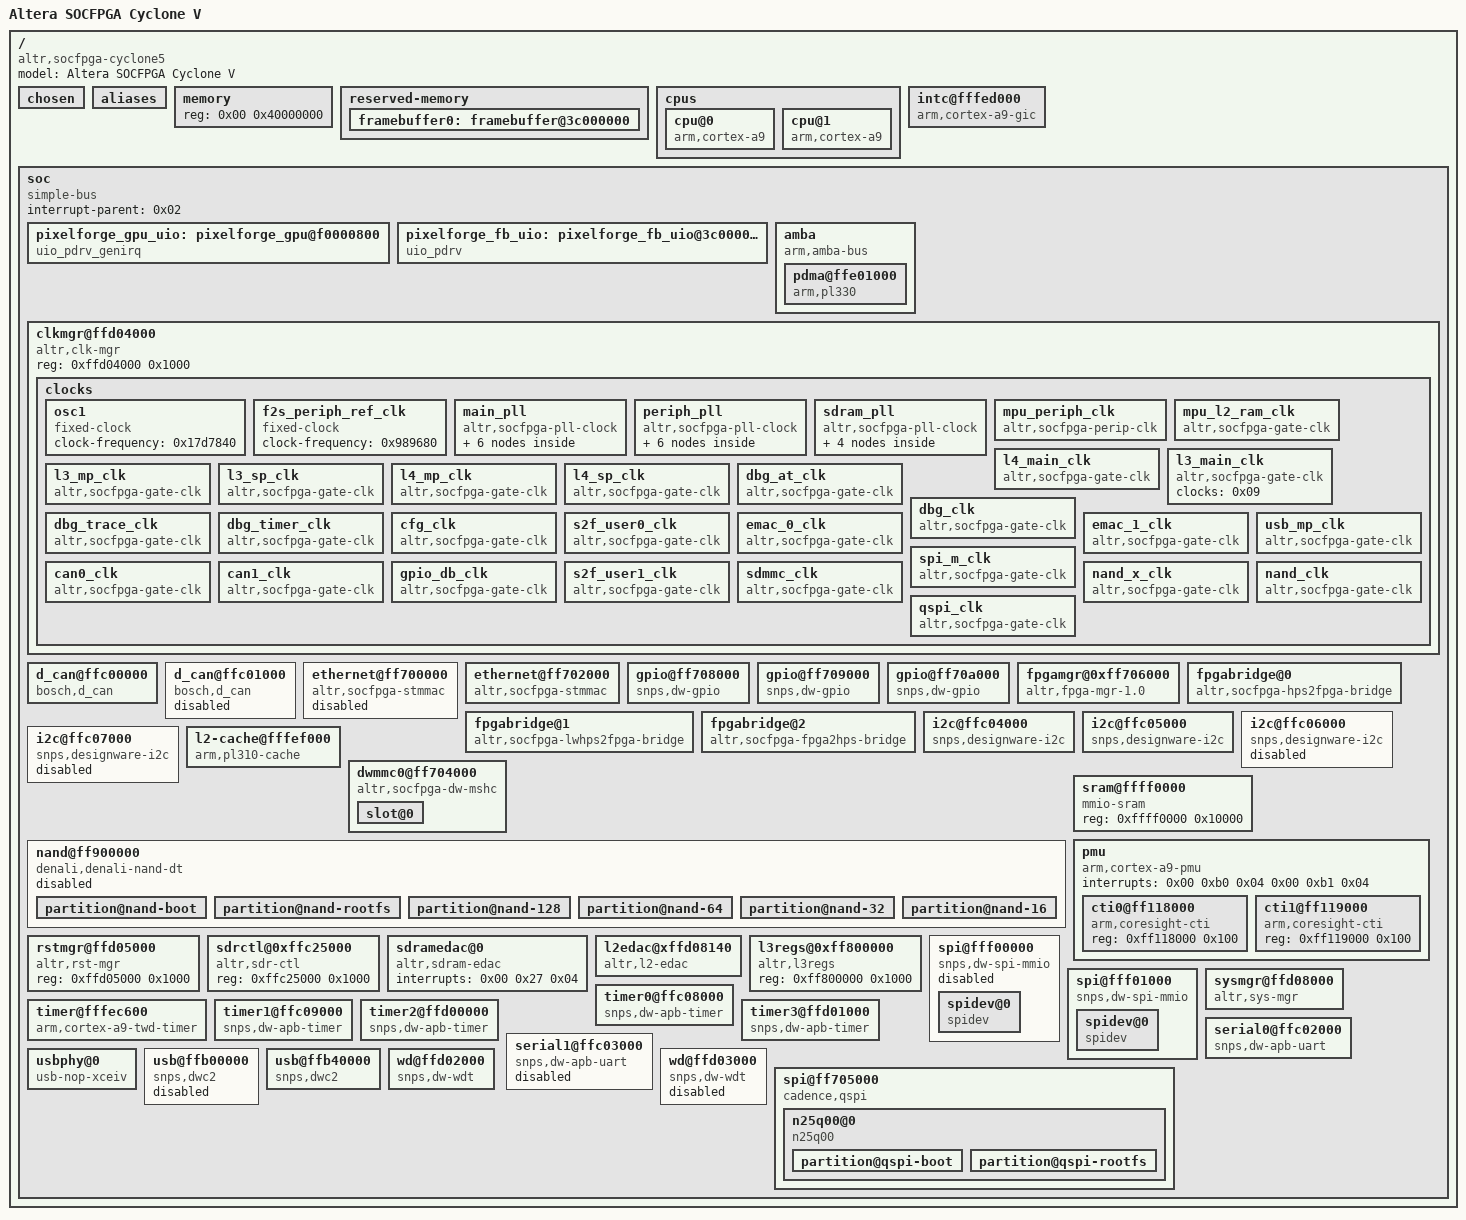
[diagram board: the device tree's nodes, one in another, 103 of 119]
/dts-v1/;

/ {
	#address-cells = <0x01>;
	#size-cells = <0x01>;
	model = "Altera SOCFPGA Cyclone V";
	compatible = "altr,socfpga-cyclone5", "altr,socfpga";

	chosen {
		bootargs = "console=ttyS0,115200 root=/dev/mmcblk0p2 rw rootwait";
	};

	aliases {
		serial0 = "/soc/serial0@ffc02000";
		serial1 = "/soc/serial1@ffc03000";
		timer0 = "/soc/timer0@ffc08000";
		timer1 = "/soc/timer1@ffc09000";
		timer2 = "/soc/timer2@ffd00000";
		timer3 = "/soc/timer3@ffd01000";
		ethernet0 = "/soc/ethernet@ff702000";
	};

	memory {
		device_type = "memory";
		reg = <0x00 0x40000000>;
	};

	/* Reserved contiguous VRAM carveout (64MB at top of 1GB SDRAM) */
	reserved-memory {
		#address-cells = <1>;
		#size-cells = <1>;
		ranges;

		/* 0x3c000000 - 0x3fffffff reserved for VRAM (color/depth/stencil/other GPU buffers) */
		framebuffer0: framebuffer@3c000000 {
			reg = <0x3c000000 0x04000000>; /* 64MB */
			no-map; /* prevent kernel usage/mapping */
		};
	};

	cpus {
		#address-cells = <0x01>;
		#size-cells = <0x00>;

		cpu@0 {
			compatible = "arm,cortex-a9";
			device_type = "cpu";
			reg = <0x00>;
			next-level-cache = <0x01>;
		};

		cpu@1 {
			compatible = "arm,cortex-a9";
			device_type = "cpu";
			reg = <0x01>;
			next-level-cache = <0x01>;
		};
	};

	intc@fffed000 {
		compatible = "arm,cortex-a9-gic";
		#interrupt-cells = <0x03>;
		interrupt-controller;
		reg = <0xfffed000 0x1000 0xfffec100 0x100>;
		linux,phandle = <0x02>;
		phandle = <0x02>;
	};

	soc {
		#address-cells = <0x01>;
		#size-cells = <0x01>;
		compatible = "simple-bus";
		device_type = "soc";
		interrupt-parent = <0x02>;
		ranges;

		/* UIO device for PixelForge GPU CSR window with IRQ3 (ready) */
		pixelforge_gpu_uio: pixelforge_gpu@f0000800 {
			compatible = "uio_pdrv_genirq";
			reg = <0xF0000800 0x00001000>;
			interrupt-parent = <0x02>;
			interrupts = <0 75 4>; /* GIC SPI 75, level-high: adjust if needed */
			uio-name = "pixelforge_gpu";
		};

		/* UIO mapping for reserved VRAM region (no IRQ) */
		pixelforge_fb_uio: pixelforge_fb_uio@3c000000 {
			compatible = "uio_pdrv";
			reg = <0x3c000000 0x04000000>;
			uio-name = "pixelforge_fb";
		};

		amba {
			compatible = "arm,amba-bus";
			#address-cells = <0x01>;
			#size-cells = <0x01>;
			ranges;

			pdma@ffe01000 {
				compatible = "arm,pl330", "arm,primecell";
				reg = <0xffe01000 0x1000>;
				#dma-cells = <0x01>;
				#dma-channels = <0x08>;
				#dma-requests = <0x20>;
				interrupts = <0x00 0x68 0x04>;
				nr-irqs = <0x09>;
				nr-valid-peri = <0x20>;
				clocks = <0x03>;
				clock-names = "apb_pclk";
				copy-align = <0x03>;
				linux,phandle = <0x1c>;
				phandle = <0x1c>;
			};
		};

		clkmgr@ffd04000 {
			compatible = "altr,clk-mgr";
			reg = <0xffd04000 0x1000>;

			clocks {
				#address-cells = <0x01>;
				#size-cells = <0x00>;

				osc1 {
					#clock-cells = <0x00>;
					compatible = "fixed-clock";
					clock-frequency = <0x17d7840>;
					linux,phandle = <0x04>;
					phandle = <0x04>;
				};

				f2s_periph_ref_clk {
					#clock-cells = <0x00>;
					compatible = "fixed-clock";
					clock-frequency = <0x989680>;
					linux,phandle = <0x12>;
					phandle = <0x12>;
				};

				main_pll {
					#address-cells = <0x01>;
					#size-cells = <0x00>;
					#clock-cells = <0x00>;
					compatible = "altr,socfpga-pll-clock";
					clocks = <0x04>;
					reg = <0x40>;
					linux,phandle = <0x05>;
					phandle = <0x05>;

					mpuclk {
						#clock-cells = <0x00>;
						compatible = "altr,socfpga-perip-clk";
						clocks = <0x05>;
						fixed-divider = <0x02>;
						reg = <0x48>;
						linux,phandle = <0x08>;
						phandle = <0x08>;
					};

					mainclk {
						#clock-cells = <0x00>;
						compatible = "altr,socfpga-perip-clk";
						clocks = <0x05>;
						fixed-divider = <0x04>;
						reg = <0x4c>;
						linux,phandle = <0x09>;
						phandle = <0x09>;
					};

					dbg_base_clk {
						#clock-cells = <0x00>;
						compatible = "altr,socfpga-perip-clk";
						clocks = <0x05>;
						fixed-divider = <0x04>;
						reg = <0x50>;
						linux,phandle = <0x0c>;
						phandle = <0x0c>;
					};

					main_qspi_clk {
						#clock-cells = <0x00>;
						compatible = "altr,socfpga-perip-clk";
						clocks = <0x05>;
						reg = <0x54>;
						linux,phandle = <0x15>;
						phandle = <0x15>;
					};

					main_nand_sdmmc_clk {
						#clock-cells = <0x00>;
						compatible = "altr,socfpga-perip-clk";
						clocks = <0x05>;
						reg = <0x58>;
						linux,phandle = <0x13>;
						phandle = <0x13>;
					};

					cfg_s2f_usr0_clk {
						#clock-cells = <0x00>;
						compatible = "altr,socfpga-perip-clk";
						clocks = <0x05>;
						reg = <0x5c>;
						linux,phandle = <0x0e>;
						phandle = <0x0e>;
					};
				};

				periph_pll {
					#address-cells = <0x01>;
					#size-cells = <0x00>;
					#clock-cells = <0x00>;
					compatible = "altr,socfpga-pll-clock";
					clocks = <0x04>;
					reg = <0x80>;
					linux,phandle = <0x06>;
					phandle = <0x06>;

					emac0_clk {
						#clock-cells = <0x00>;
						compatible = "altr,socfpga-perip-clk";
						clocks = <0x06>;
						reg = <0x88>;
						linux,phandle = <0x0f>;
						phandle = <0x0f>;
					};

					emac1_clk {
						#clock-cells = <0x00>;
						compatible = "altr,socfpga-perip-clk";
						clocks = <0x06>;
						reg = <0x8c>;
						linux,phandle = <0x10>;
						phandle = <0x10>;
					};

					per_qsi_clk {
						#clock-cells = <0x00>;
						compatible = "altr,socfpga-perip-clk";
						clocks = <0x06>;
						reg = <0x90>;
						linux,phandle = <0x16>;
						phandle = <0x16>;
					};

					per_nand_mmc_clk {
						#clock-cells = <0x00>;
						compatible = "altr,socfpga-perip-clk";
						clocks = <0x06>;
						reg = <0x94>;
						linux,phandle = <0x14>;
						phandle = <0x14>;
					};

					per_base_clk {
						#clock-cells = <0x00>;
						compatible = "altr,socfpga-perip-clk";
						clocks = <0x06>;
						reg = <0x98>;
						linux,phandle = <0x0b>;
						phandle = <0x0b>;
					};

					s2f_usr1_clk {
						#clock-cells = <0x00>;
						compatible = "altr,socfpga-perip-clk";
						clocks = <0x06>;
						reg = <0x9c>;
						linux,phandle = <0x11>;
						phandle = <0x11>;
					};
				};

				sdram_pll {
					#address-cells = <0x01>;
					#size-cells = <0x00>;
					#clock-cells = <0x00>;
					compatible = "altr,socfpga-pll-clock";
					clocks = <0x04>;
					reg = <0xc0>;
					linux,phandle = <0x07>;
					phandle = <0x07>;

					ddr_dqs_clk {
						#clock-cells = <0x00>;
						compatible = "altr,socfpga-perip-clk";
						clocks = <0x07>;
						reg = <0xc8>;
					};

					ddr_2x_dqs_clk {
						#clock-cells = <0x00>;
						compatible = "altr,socfpga-perip-clk";
						clocks = <0x07>;
						reg = <0xcc>;
					};

					ddr_dq_clk {
						#clock-cells = <0x00>;
						compatible = "altr,socfpga-perip-clk";
						clocks = <0x07>;
						reg = <0xd0>;
					};

					s2f_usr2_clk {
						#clock-cells = <0x00>;
						compatible = "altr,socfpga-perip-clk";
						clocks = <0x07>;
						reg = <0xd4>;
					};
				};

				mpu_periph_clk {
					#clock-cells = <0x00>;
					compatible = "altr,socfpga-perip-clk";
					clocks = <0x08>;
					fixed-divider = <0x04>;
					linux,phandle = <0x1d>;
					phandle = <0x1d>;
				};

				mpu_l2_ram_clk {
					#clock-cells = <0x00>;
					compatible = "altr,socfpga-gate-clk";
					clocks = <0x08>;
					fixed-divider = <0x02>;
				};

				l4_main_clk {
					#clock-cells = <0x00>;
					compatible = "altr,socfpga-gate-clk";
					clocks = <0x09>;
					clk-gate = <0x60 0x00>;
					linux,phandle = <0x03>;
					phandle = <0x03>;
				};

				l3_main_clk {
					#clock-cells = <0x00>;
					compatible = "altr,socfpga-gate-clk";
					clocks = <0x09>;
				};

				l3_mp_clk {
					#clock-cells = <0x00>;
					compatible = "altr,socfpga-gate-clk";
					clocks = <0x09>;
					div-reg = <0x64 0x00 0x02>;
					clk-gate = <0x60 0x01>;
					linux,phandle = <0x0a>;
					phandle = <0x0a>;
				};

				l3_sp_clk {
					#clock-cells = <0x00>;
					compatible = "altr,socfpga-gate-clk";
					clocks = <0x0a>;
					div-reg = <0x64 0x02 0x02>;
				};

				l4_mp_clk {
					#clock-cells = <0x00>;
					compatible = "altr,socfpga-gate-clk";
					clocks = <0x09 0x0b>;
					div-reg = <0x64 0x04 0x03>;
					clk-gate = <0x60 0x02>;
					linux,phandle = <0x19>;
					phandle = <0x19>;
				};

				l4_sp_clk {
					#clock-cells = <0x00>;
					compatible = "altr,socfpga-gate-clk";
					clocks = <0x09 0x0b>;
					div-reg = <0x64 0x07 0x03>;
					clk-gate = <0x60 0x03>;
					linux,phandle = <0x1e>;
					phandle = <0x1e>;
				};

				dbg_at_clk {
					#clock-cells = <0x00>;
					compatible = "altr,socfpga-gate-clk";
					clocks = <0x0c>;
					div-reg = <0x68 0x00 0x02>;
					clk-gate = <0x60 0x04>;
					linux,phandle = <0x0d>;
					phandle = <0x0d>;
				};

				dbg_clk {
					#clock-cells = <0x00>;
					compatible = "altr,socfpga-gate-clk";
					clocks = <0x0d>;
					div-reg = <0x68 0x02 0x02>;
					clk-gate = <0x60 0x05>;
				};

				dbg_trace_clk {
					#clock-cells = <0x00>;
					compatible = "altr,socfpga-gate-clk";
					clocks = <0x0c>;
					div-reg = <0x6c 0x00 0x03>;
					clk-gate = <0x60 0x06>;
				};

				dbg_timer_clk {
					#clock-cells = <0x00>;
					compatible = "altr,socfpga-gate-clk";
					clocks = <0x0c>;
					clk-gate = <0x60 0x07>;
				};

				cfg_clk {
					#clock-cells = <0x00>;
					compatible = "altr,socfpga-gate-clk";
					clocks = <0x0e>;
					clk-gate = <0x60 0x08>;
				};

				s2f_user0_clk {
					#clock-cells = <0x00>;
					compatible = "altr,socfpga-gate-clk";
					clocks = <0x0e>;
					clk-gate = <0x60 0x09>;
				};

				emac_0_clk {
					#clock-cells = <0x00>;
					compatible = "altr,socfpga-gate-clk";
					clocks = <0x0f>;
					clk-gate = <0xa0 0x00>;
				};

				emac_1_clk {
					#clock-cells = <0x00>;
					compatible = "altr,socfpga-gate-clk";
					clocks = <0x10>;
					clk-gate = <0xa0 0x01>;
				};

				usb_mp_clk {
					#clock-cells = <0x00>;
					compatible = "altr,socfpga-gate-clk";
					clocks = <0x0b>;
					clk-gate = <0xa0 0x02>;
					div-reg = <0xa4 0x00 0x03>;
					linux,phandle = <0x1f>;
					phandle = <0x1f>;
				};

				spi_m_clk {
					#clock-cells = <0x00>;
					compatible = "altr,socfpga-gate-clk";
					clocks = <0x0b>;
					clk-gate = <0xa0 0x03>;
					div-reg = <0xa4 0x03 0x03>;
				};

				can0_clk {
					#clock-cells = <0x00>;
					compatible = "altr,socfpga-gate-clk";
					clocks = <0x0b>;
					clk-gate = <0xa0 0x04>;
					div-reg = <0xa4 0x06 0x03>;
					linux,phandle = <0x17>;
					phandle = <0x17>;
				};

				can1_clk {
					#clock-cells = <0x00>;
					compatible = "altr,socfpga-gate-clk";
					clocks = <0x0b>;
					clk-gate = <0xa0 0x05>;
					div-reg = <0xa4 0x09 0x03>;
					linux,phandle = <0x18>;
					phandle = <0x18>;
				};

				gpio_db_clk {
					#clock-cells = <0x00>;
					compatible = "altr,socfpga-gate-clk";
					clocks = <0x0b>;
					clk-gate = <0xa0 0x06>;
					div-reg = <0xa8 0x00 0x18>;
				};

				s2f_user1_clk {
					#clock-cells = <0x00>;
					compatible = "altr,socfpga-gate-clk";
					clocks = <0x11>;
					clk-gate = <0xa0 0x07>;
				};

				sdmmc_clk {
					#clock-cells = <0x00>;
					compatible = "altr,socfpga-gate-clk";
					clocks = <0x12 0x13 0x14>;
					clk-gate = <0xa0 0x08>;
					linux,phandle = <0x1a>;
					phandle = <0x1a>;
				};

				nand_x_clk {
					#clock-cells = <0x00>;
					compatible = "altr,socfpga-gate-clk";
					clocks = <0x12 0x13 0x14>;
					clk-gate = <0xa0 0x09>;
				};

				nand_clk {
					#clock-cells = <0x00>;
					compatible = "altr,socfpga-gate-clk";
					clocks = <0x12 0x13 0x14>;
					clk-gate = <0xa0 0x0a>;
					fixed-divider = <0x04>;
					linux,phandle = <0x1b>;
					phandle = <0x1b>;
				};

				qspi_clk {
					#clock-cells = <0x00>;
					compatible = "altr,socfpga-gate-clk";
					clocks = <0x12 0x15 0x16>;
					clk-gate = <0xa0 0x0b>;
				};
			};
		};

		d_can@ffc00000 {
			compatible = "bosch,d_can";
			reg = <0xffc00000 0x1000>;
			interrupts = <0x00 0x83 0x04 0x00 0x84 0x04>;
			clocks = <0x17>;
			status = "okay";
		};

		d_can@ffc01000 {
			compatible = "bosch,d_can";
			reg = <0xffc01000 0x1000>;
			interrupts = <0x00 0x87 0x04 0x00 0x88 0x04>;
			clocks = <0x18>;
			status = "disabled";
		};

		ethernet@ff700000 {
			compatible = "altr,socfpga-stmmac", "snps,dwmac-3.70a", "snps,dwmac";
			reg = <0xff700000 0x2000>;
			interrupts = <0x00 0x73 0x04>;
			interrupt-names = "macirq";
			mac-address = [00 00 00 00 00 00];
			clocks = <0x0f>;
			clock-names = "stmmaceth";
			status = "disabled";
		};

		ethernet@ff702000 {
			compatible = "altr,socfpga-stmmac", "snps,dwmac-3.70a", "snps,dwmac";
			reg = <0xff702000 0x2000>;
			interrupts = <0x00 0x78 0x04>;
			interrupt-names = "macirq";
			mac-address = [00 00 00 00 00 00];
			clocks = <0x10>;
			clock-names = "stmmaceth";
			status = "okay";
			phy-mode = "rgmii";
			snps,phy-addr = <0xffffffff>;
			rxd0-skew-ps = <0x00>;
			rxd1-skew-ps = <0x00>;
			rxd2-skew-ps = <0x00>;
			rxd3-skew-ps = <0x00>;
			txen-skew-ps = <0x00>;
			txc-skew-ps = <0xa28>;
			rxdv-skew-ps = <0x00>;
			rxc-skew-ps = <0x7d0>;
			snps,max-mtu = <0xed8>;
		};

		gpio@ff708000 {
			compatible = "snps,dw-gpio";
			reg = <0xff708000 0x1000>;
			interrupts = <0x00 0xa4 0x04>;
			width = <0x1d>;
			virtual_irq_start = <0x101>;
			interrupt-controller;
			#interrupt-cells = <0x02>;
			gpio-controller;
			#gpio-cells = <0x02>;
			clocks = <0x0b>;
		};

		gpio@ff709000 {
			compatible = "snps,dw-gpio";
			reg = <0xff709000 0x1000>;
			interrupts = <0x00 0xa5 0x04>;
			width = <0x1d>;
			virtual_irq_start = <0x11e>;
			interrupt-controller;
			#interrupt-cells = <0x02>;
			gpio-controller;
			#gpio-cells = <0x02>;
			clocks = <0x0b>;
		};

		gpio@ff70a000 {
			compatible = "snps,dw-gpio";
			reg = <0xff70a000 0x1000>;
			interrupts = <0x00 0xa6 0x04>;
			width = <0x1b>;
			virtual_irq_start = <0x13b>;
			interrupt-controller;
			#interrupt-cells = <0x02>;
			gpio-controller;
			#gpio-cells = <0x02>;
			clocks = <0x0b>;
		};

		fpgamgr@0xff706000 {
			compatible = "altr,fpga-mgr-1.0", "altr,fpga-mgr";
			transport = "mmio";
			reg = <0xff706000 0x1000 0xffb90000 0x1000>;
			interrupts = <0x00 0xaf 0x04>;
		};

		fpgabridge@0 {
			compatible = "altr,socfpga-hps2fpga-bridge";
			label = "hps2fpga";
			clocks = <0x03>;
		};

		fpgabridge@1 {
			compatible = "altr,socfpga-lwhps2fpga-bridge";
			label = "lwhps2fpga";
			clocks = <0x03>;
		};

		fpgabridge@2 {
			compatible = "altr,socfpga-fpga2hps-bridge";
			label = "fpga2hps";
			clocks = <0x03>;
		};

		i2c@ffc04000 {
			#address-cells = <0x01>;
			#size-cells = <0x00>;
			compatible = "snps,designware-i2c";
			reg = <0xffc04000 0x1000>;
			interrupts = <0x00 0x9e 0x04>;
			clocks = <0x0b>;
			status = "okay";
			speed-mode = <0x00>;
		};

		i2c@ffc05000 {
			#address-cells = <0x01>;
			#size-cells = <0x00>;
			compatible = "snps,designware-i2c";
			reg = <0xffc05000 0x1000>;
			interrupts = <0x00 0x9f 0x04>;
			clocks = <0x0b>;
			status = "okay";
			speed-mode = <0x00>;
		};

		i2c@ffc06000 {
			#address-cells = <0x01>;
			#size-cells = <0x00>;
			compatible = "snps,designware-i2c";
			reg = <0xffc06000 0x1000>;
			interrupts = <0x00 0xa0 0x04>;
			clocks = <0x0b>;
			status = "disabled";
		};

		i2c@ffc07000 {
			#address-cells = <0x01>;
			#size-cells = <0x00>;
			compatible = "snps,designware-i2c";
			reg = <0xffc07000 0x1000>;
			interrupts = <0x00 0xa1 0x04>;
			clocks = <0x0b>;
			status = "disabled";
		};

		l2-cache@fffef000 {
			compatible = "arm,pl310-cache", "syscon";
			reg = <0xfffef000 0x1000>;
			interrupts = <0x00 0x26 0x04>;
			cache-unified;
			cache-level = <0x02>;
			arm,tag-latency = <0x01 0x01 0x01>;
			arm,data-latency = <0x02 0x01 0x01>;
			linux,phandle = <0x01>;
			phandle = <0x01>;
		};

		dwmmc0@ff704000 {
			compatible = "altr,socfpga-dw-mshc";
			reg = <0xff704000 0x1000>;
			interrupts = <0x00 0x8b 0x04>;
			fifo-depth = <0x400>;
			#address-cells = <0x01>;
			#size-cells = <0x00>;
			clocks = <0x19 0x1a>;
			clock-names = "biu", "ciu";
			num-slots = <0x01>;
			supports-highspeed;
			broken-cd;
			altr,dw-mshc-ciu-div = <0x03>;
			altr,dw-mshc-sdr-timing = <0x00 0x03>;

			slot@0 {
				reg = <0x00>;
				bus-width = <0x04>;
			};
		};

		nand@ff900000 {
			#address-cells = <0x01>;
			#size-cells = <0x01>;
			compatible = "denali,denali-nand-dt";
			reg = <0xff900000 0x100000 0xffb80000 0x10000>;
			reg-names = "nand_data", "denali_reg";
			interrupts = <0x00 0x90 0x04>;
			dma-mask = <0xffffffff>;
			clocks = <0x1b>;
			have-hw-ecc-fixup;
			status = "disabled";

			partition@nand-boot {
				label = "NAND Flash Boot Area 8MB";
				reg = <0x00 0x800000>;
			};

			partition@nand-rootfs {
				label = "NAND Flash jffs2 Root Filesystem 128MB";
				reg = <0x800000 0x8000000>;
			};

			partition@nand-128 {
				label = "NAND Flash 128 MB";
				reg = <0x8800000 0x8000000>;
			};

			partition@nand-64 {
				label = "NAND Flash 64 MB";
				reg = <0x10800000 0x4000000>;
			};

			partition@nand-32 {
				label = "NAND Flash 32 MB";
				reg = <0x14800000 0x2000000>;
			};

			partition@nand-16 {
				label = "NAND Flash 16 MB";
				reg = <0x16800000 0x1000000>;
			};
		};

		sram@ffff0000 {
			compatible = "mmio-sram";
			reg = <0xffff0000 0x10000>;
		};

		pmu {
			#address-cells = <0x01>;
			#size-cells = <0x01>;
			compatible = "arm,cortex-a9-pmu";
			interrupts = <0x00 0xb0 0x04 0x00 0xb1 0x04>;
			ranges;

			cti0@ff118000 {
				compatible = "arm,coresight-cti";
				reg = <0xff118000 0x100>;
			};

			cti1@ff119000 {
				compatible = "arm,coresight-cti";
				reg = <0xff119000 0x100>;
			};
		};

		rstmgr@ffd05000 {
			compatible = "altr,rst-mgr", "syscon";
			reg = <0xffd05000 0x1000>;
		};

		sdrctl@0xffc25000 {
			compatible = "altr,sdr-ctl", "syscon";
			reg = <0xffc25000 0x1000>;
		};

		sdramedac@0 {
			compatible = "altr,sdram-edac";
			interrupts = <0x00 0x27 0x04>;
		};

		l2edac@xffd08140 {
			compatible = "altr,l2-edac";
			reg = <0xffd08140 0x04>;
			interrupts = <0x00 0x24 0x01 0x00 0x25 0x01>;
		};

		l3regs@0xff800000 {
			compatible = "altr,l3regs", "syscon";
			reg = <0xff800000 0x1000>;
		};

		spi@fff00000 {
			compatible = "snps,dw-spi-mmio";
			#address-cells = <0x01>;
			#size-cells = <0x00>;
			reg = <0xfff00000 0x1000>;
			interrupts = <0x00 0x9a 0x04>;
			num-chipselect = <0x04>;
			bus-num = <0x00>;
			tx-dma-channel = <0x1c 0x10>;
			rx-dma-channel = <0x1c 0x11>;
			clocks = <0x0b>;
			status = "disabled";

			spidev@0 {
				compatible = "spidev";
				reg = <0x00>;
				spi-max-frequency = <0x5f5e100>;
				enable-dma = <0x01>;
			};
		};

		spi@fff01000 {
			compatible = "snps,dw-spi-mmio";
			#address-cells = <0x01>;
			#size-cells = <0x00>;
			reg = <0xfff01000 0x1000>;
			interrupts = <0x00 0x9b 0x04>;
			num-chipselect = <0x04>;
			bus-num = <0x01>;
			tx-dma-channel = <0x1c 0x14>;
			rx-dma-channel = <0x1c 0x15>;
			clocks = <0x0b>;

			spidev@0 {
				compatible = "spidev";
				reg = <0x00>;
				spi-max-frequency = <0x5f5e100>;
				enable-dma = <0x01>;
			};
		};

		sysmgr@ffd08000 {
			compatible = "altr,sys-mgr", "syscon";
			reg = <0xffd08000 0x4000>;
			cpu1-start-addr = <0xffd080c4>;
		};

		timer@fffec600 {
			compatible = "arm,cortex-a9-twd-timer";
			reg = <0xfffec600 0x100>;
			interrupts = <0x01 0x0d 0xf04>;
			clocks = <0x1d>;
		};

		timer0@ffc08000 {
			compatible = "snps,dw-apb-timer";
			interrupts = <0x00 0xa7 0x04>;
			reg = <0xffc08000 0x1000>;
			clocks = <0x1e>;
			clock-names = "timer";
		};

		timer1@ffc09000 {
			compatible = "snps,dw-apb-timer";
			interrupts = <0x00 0xa8 0x04>;
			reg = <0xffc09000 0x1000>;
			clocks = <0x1e>;
			clock-names = "timer";
		};

		timer2@ffd00000 {
			compatible = "snps,dw-apb-timer";
			interrupts = <0x00 0xa9 0x04>;
			reg = <0xffd00000 0x1000>;
			clocks = <0x04>;
			clock-names = "timer";
		};

		timer3@ffd01000 {
			compatible = "snps,dw-apb-timer";
			interrupts = <0x00 0xaa 0x04>;
			reg = <0xffd01000 0x1000>;
			clocks = <0x04>;
			clock-names = "timer";
		};

		serial0@ffc02000 {
			compatible = "snps,dw-apb-uart";
			reg = <0xffc02000 0x1000>;
			interrupts = <0x00 0xa2 0x04>;
			reg-shift = <0x02>;
			reg-io-width = <0x04>;
			clocks = <0x1e>;
			status = "okay";
		};

		serial1@ffc03000 {
			compatible = "snps,dw-apb-uart";
			reg = <0xffc03000 0x1000>;
			interrupts = <0x00 0xa3 0x04>;
			reg-shift = <0x02>;
			reg-io-width = <0x04>;
			clocks = <0x1e>;
			status = "disabled";
		};

		usbphy@0 {
			#phy-cells = <0x00>;
			compatible = "usb-nop-xceiv";
			status = "okay";
			linux,phandle = <0x20>;
			phandle = <0x20>;
		};

		usb@ffb00000 {
			compatible = "snps,dwc2";
			reg = <0xffb00000 0xffff>;
			interrupts = <0x00 0x7d 0x04>;
			clocks = <0x1f>;
			clock-names = "otg";
			phys = <0x20>;
			phy-names = "usb2-phy";
			enable-dynamic-fifo = <0x01>;
			host-rx-fifo-size = <0xa00>;
			host-perio-tx-fifo-size = <0xa00>;
			host-nperio-tx-fifo-size = <0xa00>;
			dma-desc-enable = <0x00>;
			status = "disabled";
		};

		usb@ffb40000 {
			compatible = "snps,dwc2";
			reg = <0xffb40000 0xffff>;
			interrupts = <0x00 0x80 0x04>;
			clocks = <0x1f>;
			clock-names = "otg";
			phys = <0x20>;
			phy-names = "usb2-phy";
			enable-dynamic-fifo = <0x01>;
			host-rx-fifo-size = <0xa00>;
			host-perio-tx-fifo-size = <0xa00>;
			host-nperio-tx-fifo-size = <0xa00>;
			dma-desc-enable = <0x00>;
			status = "okay";
		};

		wd@ffd02000 {
			compatible = "snps,dw-wdt";
			reg = <0xffd02000 0x1000>;
			interrupts = <0x00 0xab 0x04>;
			clocks = <0x0b>;
			status = "okay";
		};

		wd@ffd03000 {
			compatible = "snps,dw-wdt";
			reg = <0xffd03000 0x1000>;
			interrupts = <0x00 0xac 0x04>;
			clocks = <0x0b>;
			status = "disabled";
		};

		spi@ff705000 {
			compatible = "cadence,qspi";
			#address-cells = <0x01>;
			#size-cells = <0x00>;
			reg = <0xff705000 0x1000 0xffa00000 0x1000>;
			interrupts = <0x00 0x97 0x04>;
			master-ref-clk = <0x17d78400>;
			ext-decoder = <0x00>;
			num-chipselect = <0x04>;
			fifo-depth = <0x80>;
			bus-num = <0x02>;

			n25q00@0 {
				#address-cells = <0x01>;
				#size-cells = <0x01>;
				compatible = "n25q00";
				reg = <0x00>;
				spi-max-frequency = <0x5f5e100>;
				m25p,fast-read;
				page-size = <0x100>;
				block-size = <0x10>;
				read-delay = <0x04>;
				tshsl-ns = <0x32>;
				tsd2d-ns = <0x32>;
				tchsh-ns = <0x04>;
				tslch-ns = <0x04>;

				partition@qspi-boot {
					label = "Flash 0 Raw Data";
					reg = <0x00 0x800000>;
				};

				partition@qspi-rootfs {
					label = "Flash 0 jffs2 Filesystem";
					reg = <0x800000 0x7800000>;
				};
			};
		};
	};
};
